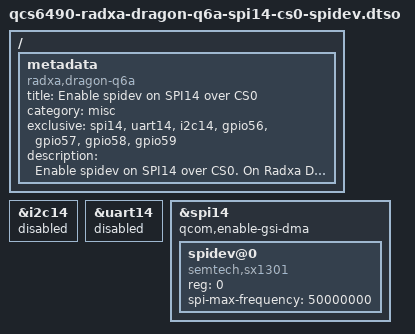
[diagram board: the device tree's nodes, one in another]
// SPDX-License-Identifier: BSD-3-Clause
/*
 * Copyright (c) 2025 Radxa Computer (Shenzhen) Co., Ltd.
 */

/dts-v1/;
/plugin/;

/ {
    metadata {
        title = "Enable spidev on SPI14 over CS0";
        compatible = "radxa,dragon-q6a";
        category = "misc";
        exclusive = "spi14", "uart14", "i2c14", "gpio56", "gpio57", "gpio58", "gpio59";
        description = "Enable spidev on SPI14 over CS0. 
On Radxa Dragon Q6A, this is pin 22(mosi), 33(miso), 36(cs0), 37(sclk).";
    };
};

&i2c14 {
	status = "disabled";
};

&uart14 {
	status = "disabled";
};

&spi14 {
	qcom,enable-gsi-dma;
	status = "okay";
	
	spidev@0 {
		compatible = "semtech,sx1301";
		status = "okay";
		reg = <0>;
		spi-max-frequency = <50000000>;
	};
};
